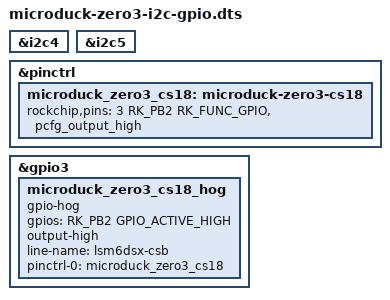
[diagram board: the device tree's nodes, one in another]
/dts-v1/;
/plugin/;

#include <dt-bindings/gpio/gpio.h>
#include <dt-bindings/pinctrl/rockchip.h>

/*
 * Radxa ZERO 3:
 *   I2C4 M0: header pins 27/28
 *   I2C5 M0: header pins 29/31
 *   header pin 18: GPIO3_B2 (gpio3 line 10), held high for LSM6DSx CSB
 */

&i2c4 {
	status = "okay";
};

&i2c5 {
	status = "okay";
};

&pinctrl {
	microduck_zero3_cs18: microduck-zero3-cs18 {
		rockchip,pins = <3 RK_PB2 RK_FUNC_GPIO &pcfg_output_high>;
	};
};

&gpio3 {
	microduck_zero3_cs18_hog {
		gpio-hog;
		gpios = <RK_PB2 GPIO_ACTIVE_HIGH>;
		output-high;
		line-name = "lsm6dsx-csb";
		pinctrl-names = "default";
		pinctrl-0 = <&microduck_zero3_cs18>;
	};
};
